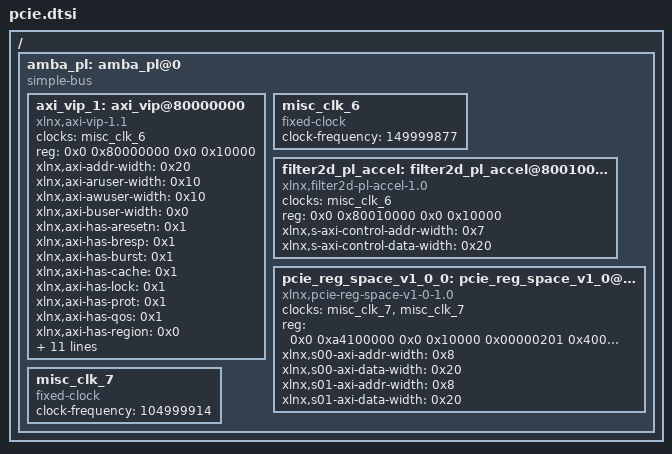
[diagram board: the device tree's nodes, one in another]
/*
 * CAUTION: This file is automatically generated by Xilinx.
 * Version:  
 * Today is: Mon Apr  5 05:11:19 2021
 */


/ {
	amba_pl: amba_pl@0 {
		#address-cells = <2>;
		#size-cells = <2>;
		compatible = "simple-bus";
		ranges ;
		axi_vip_1: axi_vip@80000000 {
			clock-names = "aclk";
			clocks = <&misc_clk_6>;
			compatible = "xlnx,axi-vip-1.1";
			reg = <0x0 0x80000000 0x0 0x10000>;
			xlnx,axi-addr-width = <0x20>;
			xlnx,axi-aruser-width = <0x10>;
			xlnx,axi-awuser-width = <0x10>;
			xlnx,axi-buser-width = <0x0>;
			xlnx,axi-has-aresetn = <0x1>;
			xlnx,axi-has-bresp = <0x1>;
			xlnx,axi-has-burst = <0x1>;
			xlnx,axi-has-cache = <0x1>;
			xlnx,axi-has-lock = <0x1>;
			xlnx,axi-has-prot = <0x1>;
			xlnx,axi-has-qos = <0x1>;
			xlnx,axi-has-region = <0x0>;
			xlnx,axi-has-rresp = <0x1>;
			xlnx,axi-has-wstrb = <0x1>;
			xlnx,axi-interface-mode = <0x2>;
			xlnx,axi-protocol = <0x0>;
			xlnx,axi-rdata-width = <0x20>;
			xlnx,axi-rid-width = <0x0>;
			xlnx,axi-ruser-width = <0x0>;
			xlnx,axi-supports-narrow = <0x0>;
			xlnx,axi-wdata-width = <0x20>;
			xlnx,axi-wid-width = <0x0>;
			xlnx,axi-wuser-width = <0x0>;
		};
		misc_clk_6: misc_clk_6 {
			#clock-cells = <0>;
			clock-frequency = <149999877>;
			compatible = "fixed-clock";
		};
		filter2d_pl_accel: filter2d_pl_accel@80010000 {
			clock-names = "ap_clk";
			clocks = <&misc_clk_6>;
			compatible = "xlnx,filter2d-pl-accel-1.0";
			reg = <0x0 0x80010000 0x0 0x10000>;
			xlnx,s-axi-control-addr-width = <0x7>;
			xlnx,s-axi-control-data-width = <0x20>;
		};
		pcie_reg_space_v1_0_0: pcie_reg_space_v1_0@a4100000 {
			clock-names = "s00_axi_aclk", "s01_axi_aclk";
			clocks = <&misc_clk_7>, <&misc_clk_7>;
			compatible = "xlnx,pcie-reg-space-v1-0-1.0";
			reg = <0x0 0xa4100000 0x0 0x10000 0x00000201 0x40000000 0x0 0x10000>;
			xlnx,s00-axi-addr-width = <0x8>;
			xlnx,s00-axi-data-width = <0x20>;
			xlnx,s01-axi-addr-width = <0x8>;
			xlnx,s01-axi-data-width = <0x20>;
		};
		misc_clk_7: misc_clk_7 {
			#clock-cells = <0>;
			clock-frequency = <104999914>;
			compatible = "fixed-clock";
		};
	};
};
